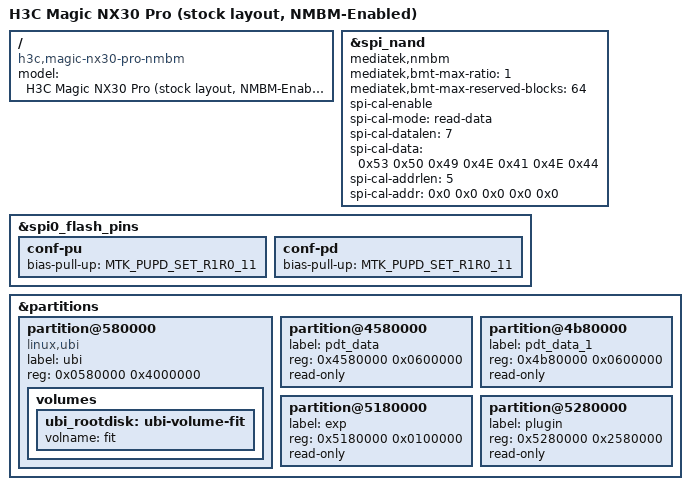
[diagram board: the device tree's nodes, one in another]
// SPDX-License-Identifier: GPL-2.0-or-later OR MIT

/dts-v1/;
#include "mt7981b-h3c-magic-nx30-pro.dtsi"

/ {
	model = "H3C Magic NX30 Pro (stock layout, NMBM-Enabled)";
	compatible = "h3c,magic-nx30-pro-nmbm", "mediatek,mt7981";
};

&spi_nand {
	mediatek,nmbm;
	mediatek,bmt-max-ratio = <1>;
	mediatek,bmt-max-reserved-blocks = <64>;

	spi-cal-enable;
	spi-cal-mode = "read-data";
	spi-cal-datalen = <7>;
	spi-cal-data = /bits/ 8 <0x53 0x50 0x49 0x4E 0x41 0x4E 0x44>;
	spi-cal-addrlen = <5>;
	spi-cal-addr = /bits/ 32 <0x0 0x0 0x0 0x0 0x0>;
};

&spi0_flash_pins {
	conf-pu {
		/delete-property/ mediatek,pull-up-adv;
		bias-pull-up = <MTK_PUPD_SET_R1R0_11>;
	};

	conf-pd {
		/delete-property/ mediatek,pull-up-adv;
		bias-pull-up = <MTK_PUPD_SET_R1R0_11>;
	};
};

&partitions {
    partition@580000 {
        label = "ubi";
        reg = <0x0580000 0x4000000>;
		compatible = "linux,ubi";

		volumes {
			ubi_rootdisk: ubi-volume-fit {
				volname = "fit";
			};
		};
    };

    /* yaffs partition */
    partition@4580000 {
        label = "pdt_data";
        reg = <0x4580000 0x0600000>;
        read-only;
    };

    /* yaffs partition */
    partition@4b80000 {
        label = "pdt_data_1";
        reg = <0x4b80000 0x0600000>;
        read-only;
    };

    partition@5180000 {
        label = "exp";
        reg = <0x5180000 0x0100000>;
        read-only;
    };

    partition@5280000 {
        label = "plugin";
        reg = <0x5280000 0x2580000>;
        read-only;
    };
};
